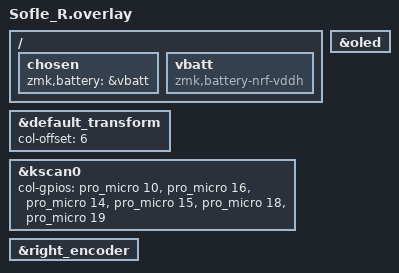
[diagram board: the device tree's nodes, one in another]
/*
 * Copyright (c) 2020 Ryan Cross
 *
 * SPDX-License-Identifier: MIT
 */

#include "Sofle.dtsi"

&default_transform {
    col-offset = <6>;
};
&kscan0 {
    col-gpios
        = <&pro_micro 10 GPIO_ACTIVE_HIGH>
        , <&pro_micro 16 GPIO_ACTIVE_HIGH>
        , <&pro_micro 14 GPIO_ACTIVE_HIGH>
        , <&pro_micro 15 GPIO_ACTIVE_HIGH>
        , <&pro_micro 18 GPIO_ACTIVE_HIGH>
        , <&pro_micro 19 GPIO_ACTIVE_HIGH>
        ;
};

&right_encoder {
    status = "okay";
};

// Right OLED is mounted 180 degrees rotated relative to the left one;
// clearing both remap flags flips it back to center/correct orientation.
&oled {
    /delete-property/ segment-remap;
    /delete-property/ com-invdir;
};

/ {
    chosen {
      zmk,battery = &vbatt;
    };

    vbatt: vbatt {
        compatible = "zmk,battery-nrf-vddh";
    };
};
